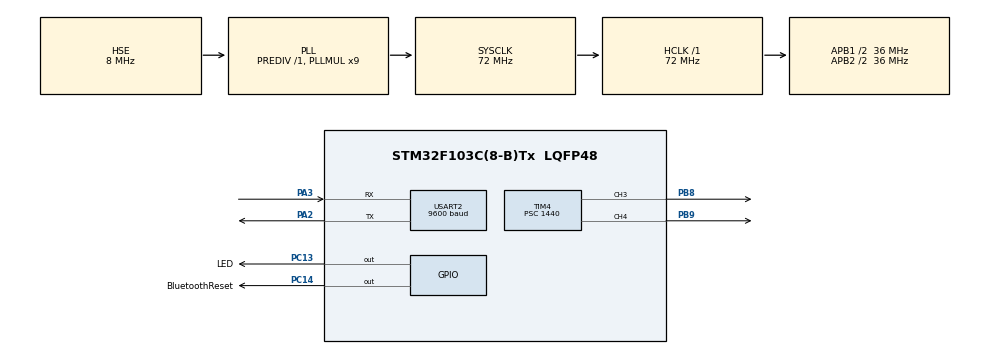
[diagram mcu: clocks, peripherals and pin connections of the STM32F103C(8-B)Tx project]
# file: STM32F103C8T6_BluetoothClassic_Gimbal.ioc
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Mcu.Family=STM32F1
Mcu.Name=STM32F103C(8-B)Tx
Mcu.Package=LQFP48
NVIC.PriorityGroup=NVIC_PRIORITYGROUP_4
NVIC.TIM2_IRQn=true\:0\:0\:false\:false\:true\:true\:true
NVIC.TIM4_IRQn=true\:0\:0\:false\:false\:true\:true\:true
NVIC.USART2_IRQn=true\:0\:0\:false\:false\:true\:true\:true
PA13.Mode=Serial_Wire
PA13.Signal=SYS_JTMS-SWDIO
PA14.Mode=Serial_Wire
PA14.Signal=SYS_JTCK-SWCLK
PA2.Mode=Asynchronous
PA2.Signal=USART2_TX
PA3.Mode=Asynchronous
PA3.Signal=USART2_RX
PB8.Signal=S_TIM4_CH3
PB9.Signal=S_TIM4_CH4
PC13-TAMPER-RTC.GPIO_Label=LED
PC13-TAMPER-RTC.GPIO_Speed=GPIO_SPEED_FREQ_HIGH
PC13-TAMPER-RTC.PinState=GPIO_PIN_SET
PC13-TAMPER-RTC.Signal=GPIO_Output
PC14-OSC32_IN.GPIO_Label=BluetoothReset
PC14-OSC32_IN.GPIO_Speed=GPIO_SPEED_FREQ_HIGH
PC14-OSC32_IN.Signal=GPIO_Output
PD0-OSC_IN.Mode=HSE-External-Oscillator
PD0-OSC_IN.Signal=RCC_OSC_IN
PD1-OSC_OUT.Mode=HSE-External-Oscillator
PD1-OSC_OUT.Signal=RCC_OSC_OUT
ProjectManager.HeapSize=0x200
ProjectManager.StackSize=0x400
ProjectManager.TargetToolchain=STM32CubeIDE
RCC.AHBFreq_Value=72000000
RCC.APB1CLKDivider=RCC_HCLK_DIV2
RCC.APB1Freq_Value=36000000
RCC.APB1TimFreq_Value=72000000
RCC.APB2CLKDivider=RCC_HCLK_DIV2
RCC.APB2Freq_Value=36000000
RCC.APB2TimFreq_Value=72000000
RCC.HCLKFreq_Value=72000000
RCC.PLLMUL=RCC_PLL_MUL9
RCC.PLLSourceVirtual=RCC_PLLSOURCE_HSE
RCC.SYSCLKFreq_VALUE=72000000
RCC.SYSCLKSource=RCC_SYSCLKSOURCE_PLLCLK
RCC.USBFreq_Value=72000000
SH.S_TIM4_CH3.0=TIM4_CH3,PWM Generation3 CH3
SH.S_TIM4_CH4.0=TIM4_CH4,PWM Generation4 CH4
TIM2.Period=1999
TIM2.Prescaler=720
TIM4.Channel-PWM\ Generation3\ CH3=TIM_CHANNEL_3
TIM4.Channel-PWM\ Generation4\ CH4=TIM_CHANNEL_4
TIM4.Period=999
TIM4.Prescaler=1440
TIM4.Pulse-PWM\ Generation3\ CH3=75
TIM4.Pulse-PWM\ Generation4\ CH4=75
USART2.BaudRate=9600
USART2.VirtualMode=VM_ASYNC
VP_TIM2_VS_ClockSourceINT.Mode=Internal
VP_TIM4_VS_ClockSourceINT.Mode=Internal
board=custom

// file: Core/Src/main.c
/* USER CODE BEGIN Header */
/**
  ******************************************************************************
  * @file           : main.c
  * @brief          : Main program body
  ******************************************************************************
  * @attention
  *
  * <h2><center>&copy; Copyright (c) 2020 STMicroelectronics.
  * All rights reserved.</center></h2>
  *
  * This software component is licensed by ST under BSD 3-Clause license,
  * the "License"; You may not use this file except in compliance with the
  * License. You may obtain a copy of the License at:
  *                        opensource.org/licenses/BSD-3-Clause
  *
  ******************************************************************************
  */
/* USER CODE END Header */

#include "main.h"

/* USER CODE BEGIN Includes */
#include "mylibrary.h"
/* USER CODE END Includes */

TIM_HandleTypeDef htim2;
TIM_HandleTypeDef htim4;

UART_HandleTypeDef huart2;

void SystemClock_Config(void);
static void MX_GPIO_Init(void);
static void MX_TIM2_Init(void);
static void MX_TIM4_Init(void);
static void MX_USART2_UART_Init(void);

int main(void)
{

  /* MCU Configuration--------------------------------------------------------*/

  /* Reset of all peripherals, Initializes the Flash interface and the Systick. */
  HAL_Init();

  /* Configure the system clock */
  SystemClock_Config();

  /* Initialize all configured peripherals */
  MX_GPIO_Init();
  MX_TIM2_Init();
  MX_TIM4_Init();
  MX_USART2_UART_Init();
  /* USER CODE BEGIN 2 */

	//Start servos
	HAL_TIM_Base_Start_IT(&htim4);
	HAL_TIM_PWM_Start(&htim4, TIM_CHANNEL_3);
	HAL_TIM_PWM_Start(&htim4, TIM_CHANNEL_4);

	//Reset Bluetooth Module
	HAL_Delay(200);
	HAL_GPIO_WritePin(BluetoothReset_GPIO_Port, BluetoothReset_Pin, SET);
	HAL_Delay(1000);
	//Name Bluetooth Gimbal
	HAL_UART_Transmit(&huart2, (uint8_t*)"AT+NAMEGimbal", strlen("AT+NAMEGimbal"), 500);
	HAL_Delay(200);

	memset(buffer, 0, sizeof(buffer));//clear buffer
	HAL_TIM_Base_Start_IT(&htim2);// start timer 2 for receiving timeout
	__HAL_UART_ENABLE_IT(&huart2, UART_IT_RXNE); // enable UART RX interrupt
	HAL_GPIO_WritePin(LED_GPIO_Port, LED_Pin, RESET);//LED ON - Everything is initialized
  /* USER CODE END 2 */

  /* Infinite loop */
  while (1)
  {

  }
}

void SystemClock_Config(void)
{
  RCC_OscInitTypeDef RCC_OscInitStruct = {0};
  RCC_ClkInitTypeDef RCC_ClkInitStruct = {0};

  /** Initializes the CPU, AHB and APB busses clocks
  */
  RCC_OscInitStruct.OscillatorType = RCC_OSCILLATORTYPE_HSE;
  RCC_OscInitStruct.HSEState = RCC_HSE_ON;
  RCC_OscInitStruct.HSEPredivValue = RCC_HSE_PREDIV_DIV1;
  RCC_OscInitStruct.HSIState = RCC_HSI_ON;
  RCC_OscInitStruct.PLL.PLLState = RCC_PLL_ON;
  RCC_OscInitStruct.PLL.PLLSource = RCC_PLLSOURCE_HSE;
  RCC_OscInitStruct.PLL.PLLMUL = RCC_PLL_MUL9;
  if (HAL_RCC_OscConfig(&RCC_OscInitStruct) != HAL_OK)
  {
    Error_Handler();
  }
  /** Initializes the CPU, AHB and APB busses clocks
  */
  RCC_ClkInitStruct.ClockType = RCC_CLOCKTYPE_HCLK|RCC_CLOCKTYPE_SYSCLK
                              |RCC_CLOCKTYPE_PCLK1|RCC_CLOCKTYPE_PCLK2;
  RCC_ClkInitStruct.SYSCLKSource = RCC_SYSCLKSOURCE_PLLCLK;
  RCC_ClkInitStruct.AHBCLKDivider = RCC_SYSCLK_DIV1;
  RCC_ClkInitStruct.APB1CLKDivider = RCC_HCLK_DIV2;
  RCC_ClkInitStruct.APB2CLKDivider = RCC_HCLK_DIV2;

  if (HAL_RCC_ClockConfig(&RCC_ClkInitStruct, FLASH_LATENCY_2) != HAL_OK)
  {
    Error_Handler();
  }
}

static void MX_TIM2_Init(void)
{

  TIM_ClockConfigTypeDef sClockSourceConfig = {0};
  TIM_MasterConfigTypeDef sMasterConfig = {0};

  htim2.Instance = TIM2;
  htim2.Init.Prescaler = 720;
  htim2.Init.CounterMode = TIM_COUNTERMODE_UP;
  htim2.Init.Period = 1999;
  htim2.Init.ClockDivision = TIM_CLOCKDIVISION_DIV1;
  htim2.Init.AutoReloadPreload = TIM_AUTORELOAD_PRELOAD_DISABLE;
  if (HAL_TIM_Base_Init(&htim2) != HAL_OK)
  {
    Error_Handler();
  }
  sClockSourceConfig.ClockSource = TIM_CLOCKSOURCE_INTERNAL;
  if (HAL_TIM_ConfigClockSource(&htim2, &sClockSourceConfig) != HAL_OK)
  {
    Error_Handler();
  }
  sMasterConfig.MasterOutputTrigger = TIM_TRGO_RESET;
  sMasterConfig.MasterSlaveMode = TIM_MASTERSLAVEMODE_DISABLE;
  if (HAL_TIMEx_MasterConfigSynchronization(&htim2, &sMasterConfig) != HAL_OK)
  {
    Error_Handler();
  }

}

static void MX_TIM4_Init(void)
{

  TIM_ClockConfigTypeDef sClockSourceConfig = {0};
  TIM_MasterConfigTypeDef sMasterConfig = {0};
  TIM_OC_InitTypeDef sConfigOC = {0};

  htim4.Instance = TIM4;
  htim4.Init.Prescaler = 1440;
  htim4.Init.CounterMode = TIM_COUNTERMODE_UP;
  htim4.Init.Period = 999;
  htim4.Init.ClockDivision = TIM_CLOCKDIVISION_DIV1;
  htim4.Init.AutoReloadPreload = TIM_AUTORELOAD_PRELOAD_DISABLE;
  if (HAL_TIM_Base_Init(&htim4) != HAL_OK)
  {
    Error_Handler();
  }
  sClockSourceConfig.ClockSource = TIM_CLOCKSOURCE_INTERNAL;
  if (HAL_TIM_ConfigClockSource(&htim4, &sClockSourceConfig) != HAL_OK)
  {
    Error_Handler();
  }
  if (HAL_TIM_PWM_Init(&htim4) != HAL_OK)
  {
    Error_Handler();
  }
  sMasterConfig.MasterOutputTrigger = TIM_TRGO_RESET;
  sMasterConfig.MasterSlaveMode = TIM_MASTERSLAVEMODE_DISABLE;
  if (HAL_TIMEx_MasterConfigSynchronization(&htim4, &sMasterConfig) != HAL_OK)
  {
    Error_Handler();
  }
  sConfigOC.OCMode = TIM_OCMODE_PWM1;
  sConfigOC.Pulse = 75;
  sConfigOC.OCPolarity = TIM_OCPOLARITY_HIGH;
  sConfigOC.OCFastMode = TIM_OCFAST_DISABLE;
  if (HAL_TIM_PWM_ConfigChannel(&htim4, &sConfigOC, TIM_CHANNEL_3) != HAL_OK)
  {
    Error_Handler();
  }
  if (HAL_TIM_PWM_ConfigChannel(&htim4, &sConfigOC, TIM_CHANNEL_4) != HAL_OK)
  {
    Error_Handler();
  }
  HAL_TIM_MspPostInit(&htim4);

}

static void MX_USART2_UART_Init(void)
{

  huart2.Instance = USART2;
  huart2.Init.BaudRate = 9600;
  huart2.Init.WordLength = UART_WORDLENGTH_8B;
  huart2.Init.StopBits = UART_STOPBITS_1;
  huart2.Init.Parity = UART_PARITY_NONE;
  huart2.Init.Mode = UART_MODE_TX_RX;
  huart2.Init.HwFlowCtl = UART_HWCONTROL_NONE;
  huart2.Init.OverSampling = UART_OVERSAMPLING_16;
  if (HAL_UART_Init(&huart2) != HAL_OK)
  {
    Error_Handler();
  }

}

static void MX_GPIO_Init(void)
{
  GPIO_InitTypeDef GPIO_InitStruct = {0};

  /* GPIO Ports Clock Enable */
  __HAL_RCC_GPIOC_CLK_ENABLE();
  __HAL_RCC_GPIOD_CLK_ENABLE();
  __HAL_RCC_GPIOA_CLK_ENABLE();
  __HAL_RCC_GPIOB_CLK_ENABLE();

  /*Configure GPIO pin Output Level */
  HAL_GPIO_WritePin(LED_GPIO_Port, LED_Pin, GPIO_PIN_SET);

  /*Configure GPIO pin Output Level */
  HAL_GPIO_WritePin(BluetoothReset_GPIO_Port, BluetoothReset_Pin, GPIO_PIN_RESET);

  /*Configure GPIO pins : LED_Pin BluetoothReset_Pin */
  GPIO_InitStruct.Pin = LED_Pin|BluetoothReset_Pin;
  GPIO_InitStruct.Mode = GPIO_MODE_OUTPUT_PP;
  GPIO_InitStruct.Pull = GPIO_NOPULL;
  GPIO_InitStruct.Speed = GPIO_SPEED_FREQ_HIGH;
  HAL_GPIO_Init(GPIOC, &GPIO_InitStruct);

}

void Error_Handler(void)
{
}

/************************ (C) COPYRIGHT STMicroelectronics *****END OF FILE****/
